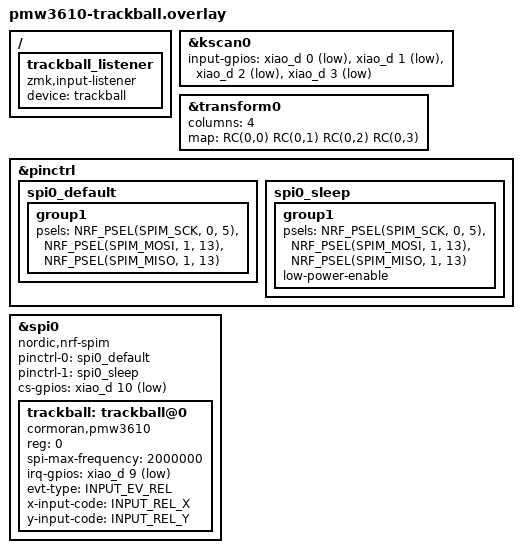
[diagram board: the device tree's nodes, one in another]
#include <zephyr/dt-bindings/input/input-event-codes.h>

/*
 * tester_xiao's default kscan wires all of xiao_d 0..10 as key inputs, which
 * conflicts with the SPI/IRQ pins used below (D5, D8, D9, D10). Restrict
 * kscan to D0-D3 and shrink the matrix transform to match.
 */
&kscan0 {
	input-gpios
		= <&xiao_d 0 (GPIO_ACTIVE_LOW | GPIO_PULL_UP)>
		, <&xiao_d 1 (GPIO_ACTIVE_LOW | GPIO_PULL_UP)>
		, <&xiao_d 2 (GPIO_ACTIVE_LOW | GPIO_PULL_UP)>
		, <&xiao_d 3 (GPIO_ACTIVE_LOW | GPIO_PULL_UP)>
		;
};

/*
 * RC(row, col) here must be the matrix-transform variant, but the keymap's
 * own includes (dt-bindings/zmk/keys.h -> modifiers.h) redefine RC(keycode)
 * as a single-argument modifier helper. Since all devicetree
 * sources/overlays share one preprocessor pass, force the matrix-transform
 * definition back for this file.
 */
#undef RC
#include <dt-bindings/zmk/matrix_transform.h>

&transform0 {
	columns = <4>;
	map = <
	RC(0,0)  RC(0,1)  RC(0,2)  RC(0,3)
	>;
};

&pinctrl {
	spi0_default: spi0_default {
		group1 {
			psels = <NRF_PSEL(SPIM_SCK, 0, 5)>, <NRF_PSEL(SPIM_MOSI, 1, 13)>, <NRF_PSEL(SPIM_MISO, 1, 13)>;
		};
	};
	spi0_sleep: spi0_sleep {
		group1 {
			psels = <NRF_PSEL(SPIM_SCK, 0, 5)>, <NRF_PSEL(SPIM_MOSI, 1, 13)>, <NRF_PSEL(SPIM_MISO, 1, 13)>;
			low-power-enable;
		};
	};
};

&spi0 {
	compatible = "nordic,nrf-spim";
	status = "okay";
	pinctrl-0 = <&spi0_default>;
	pinctrl-1 = <&spi0_sleep>;
	pinctrl-names = "default", "sleep";
	cs-gpios = <&xiao_d 10 GPIO_ACTIVE_LOW>;

	/*
	 * Burst read ON (the default -- omitting disable-burst-read): the
	 * normal/recommended mode. It needs NCS (cs-gpios, set above on &spi0)
	 * so the controller can hold chip-select across the whole burst
	 * transfer; that's configured here, so there's no reason to disable
	 * it. See ../pmw3610-trackball-no-burst for the disabled variant.
	 */
	trackball: trackball@0 {
		status = "okay";
		compatible = "cormoran,pmw3610";
		reg = <0>;
		spi-max-frequency = <2000000>;
		irq-gpios = <&xiao_d 9 (GPIO_ACTIVE_LOW | GPIO_PULL_UP)>;
		evt-type = <INPUT_EV_REL>;
		x-input-code = <INPUT_REL_X>;
		y-input-code = <INPUT_REL_Y>;
	};
};

/ {
	trackball_listener {
		compatible = "zmk,input-listener";
		device = <&trackball>;
	};
};
